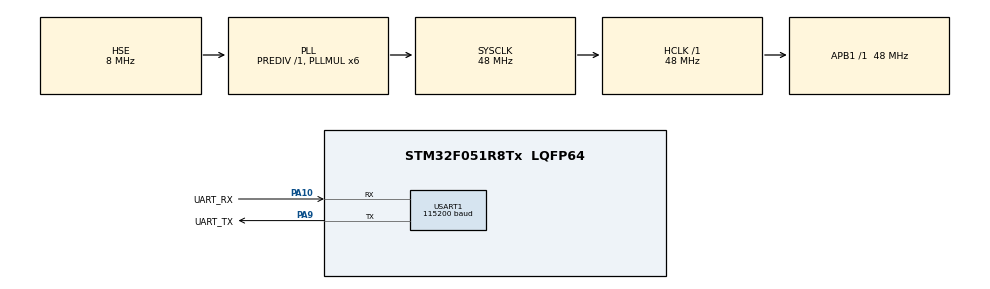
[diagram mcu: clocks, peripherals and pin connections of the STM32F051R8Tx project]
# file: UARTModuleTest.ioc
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Dma.Request0=USART1_RX
Dma.Request1=USART1_TX
Dma.USART1_RX.0.Direction=DMA_PERIPH_TO_MEMORY
Dma.USART1_RX.0.Instance=DMA1_Channel3
Dma.USART1_RX.0.MemDataAlignment=DMA_MDATAALIGN_BYTE
Dma.USART1_RX.0.MemInc=DMA_MINC_ENABLE
Dma.USART1_RX.0.Mode=DMA_NORMAL
Dma.USART1_RX.0.PeriphDataAlignment=DMA_PDATAALIGN_BYTE
Dma.USART1_RX.0.PeriphInc=DMA_PINC_DISABLE
Dma.USART1_RX.0.Priority=DMA_PRIORITY_LOW
Dma.USART1_TX.1.Direction=DMA_MEMORY_TO_PERIPH
Dma.USART1_TX.1.Instance=DMA1_Channel2
Dma.USART1_TX.1.MemDataAlignment=DMA_MDATAALIGN_BYTE
Dma.USART1_TX.1.MemInc=DMA_MINC_ENABLE
Dma.USART1_TX.1.Mode=DMA_NORMAL
Dma.USART1_TX.1.PeriphDataAlignment=DMA_PDATAALIGN_BYTE
Dma.USART1_TX.1.PeriphInc=DMA_PINC_DISABLE
Dma.USART1_TX.1.Priority=DMA_PRIORITY_LOW
Mcu.Family=STM32F0
Mcu.Name=STM32F051R8Tx
Mcu.Package=LQFP64
NVIC.DMA1_Channel2_3_IRQn=true\:0\:0\:false\:false\:true\:false\:true\:true
NVIC.USART1_IRQn=true\:0\:0\:false\:false\:true\:true\:true\:true
PA10.GPIO_Label=UART_RX
PA10.Mode=Asynchronous
PA10.Signal=USART1_RX
PA9.GPIO_Label=UART_TX
PA9.Mode=Asynchronous
PA9.Signal=USART1_TX
PF0-OSC_IN.Mode=HSE-External-Oscillator
PF0-OSC_IN.Signal=RCC_OSC_IN
PF1-OSC_OUT.Mode=HSE-External-Oscillator
PF1-OSC_OUT.Signal=RCC_OSC_OUT
ProjectManager.HeapSize=0x200
ProjectManager.StackSize=0x400
ProjectManager.TargetToolchain=MDK-ARM V5.32
RCC.AHBFreq_Value=48000000
RCC.APB1Freq_Value=48000000
RCC.APB1TimFreq_Value=48000000
RCC.HCLKFreq_Value=48000000
RCC.PLLMUL=RCC_PLL_MUL6
RCC.PLLSourceVirtual=RCC_PLLSOURCE_HSE
RCC.SYSCLKFreq_VALUE=48000000
RCC.SYSCLKSource=RCC_SYSCLKSOURCE_PLLCLK
USART1.BaudRate=115200
USART1.VirtualMode-Asynchronous=VM_ASYNC
board=custom

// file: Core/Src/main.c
/* USER CODE BEGIN Header */
/**
  ******************************************************************************
  * @file           : main.c
  * @brief          : Main program body
  ******************************************************************************
  * @attention
  *
  * Copyright (c) 2025 STMicroelectronics.
  * All rights reserved.
  *
  * This software is licensed under terms that can be found in the LICENSE file
  * in the root directory of this software component.
  * If no LICENSE file comes with this software, it is provided AS-IS.
  *
  ******************************************************************************
  */
/* USER CODE END Header */
#include "main.h"

/* USER CODE BEGIN PTD */

uint8_t msg_tx[512];
uint8_t msg_rx[16];
uint8_t* command_tx;

unsigned int buffer[3];

unsigned long Time;
/* USER CODE END PTD */

UART_HandleTypeDef huart1;
DMA_HandleTypeDef hdma_usart1_rx;
DMA_HandleTypeDef hdma_usart1_tx;

void SystemClock_Config(void);
static void MX_GPIO_Init(void);
static void MX_DMA_Init(void);
static void MX_USART1_UART_Init(void);
/* USER CODE BEGIN PFP */

void SendPackage(int *data, int len){

}

unsigned int calculateBCC(uint8_t *data, int length, bool get) // BCC CALCULATION 1-true 0-false
{
    unsigned int checksum = 0;
	if(!get){
    for (int i = 0; i < length-1; i++)
    {
        checksum ^= (int)data[i];

    }

		if(	checksum == data[length-1]){
    return 1;
		}
		else{
			return 0;
		}
	}
	else {

		  for (int i = 0; i < length-1; i++)
    {
        checksum ^= (int)data[i];

    }
		return checksum;

	}
}

void HAL_UART_RxCpltCallback(UART_HandleTypeDef *huart){          // PROBABLY NEED CALLBACK REWORK :3
    switch((int)msg_rx[0]){
		case(0x01):
				if(calculateBCC(msg_rx, 3, 0 )){
					// NEED TO MAKE CYCLE FOR LIST OF GAMES (BLALALA BLYLYLYL)
						msg_tx[0]=0x01;
						msg_tx[1]=0x01;
						msg_tx[2]=0x14;
						msg_tx[3]=calculateBCC(msg_tx, 4,1);
			    HAL_UART_Transmit(&huart1, msg_tx, 4 , 0xFFFF);}
				else{
						msg_tx[0]=0x01;
						msg_tx[1]=0xFF;
						msg_tx[2]=0xFF;
						msg_tx[3]=calculateBCC(msg_tx, 4,1);
					HAL_UART_Transmit(&huart1, msg_tx, 4 , 0xFFFF);}
		break;
		case(0x02):

		 if( ((int)msg_rx[1] == 0x0E) &&( !(int)msg_rx[2] && !(int)msg_rx[3]) && calculateBCC(msg_rx, 5, 0 ))  {
		    	HAL_UART_Transmit(&huart1, msg_tx, sprintf((char *)msg_tx, "pig\n\r"), 0xFFFF);
	 }

		break;

	}

}

/* USER CODE END PFP */

int main(void)
{

  /* MCU Configuration--------------------------------------------------------*/

  /* Reset of all peripherals, Initializes the Flash interface and the Systick. */
  HAL_Init();

  /* Configure the system clock */
  SystemClock_Config();

  /* Initialize all configured peripherals */
  MX_GPIO_Init();
  MX_DMA_Init();
  MX_USART1_UART_Init();

  /* Infinite loop */
  while (1)
  {

  }
}

void SystemClock_Config(void)
{
  RCC_OscInitTypeDef RCC_OscInitStruct = {0};
  RCC_ClkInitTypeDef RCC_ClkInitStruct = {0};
  RCC_PeriphCLKInitTypeDef PeriphClkInit = {0};

  /** Initializes the RCC Oscillators according to the specified parameters
  * in the RCC_OscInitTypeDef structure.
  */
  RCC_OscInitStruct.OscillatorType = RCC_OSCILLATORTYPE_HSE;
  RCC_OscInitStruct.HSEState = RCC_HSE_ON;
  RCC_OscInitStruct.PLL.PLLState = RCC_PLL_ON;
  RCC_OscInitStruct.PLL.PLLSource = RCC_PLLSOURCE_HSE;
  RCC_OscInitStruct.PLL.PLLMUL = RCC_PLL_MUL6;
  RCC_OscInitStruct.PLL.PREDIV = RCC_PREDIV_DIV1;
  if (HAL_RCC_OscConfig(&RCC_OscInitStruct) != HAL_OK)
  {
    Error_Handler();
  }

  /** Initializes the CPU, AHB and APB buses clocks
  */
  RCC_ClkInitStruct.ClockType = RCC_CLOCKTYPE_HCLK|RCC_CLOCKTYPE_SYSCLK
                              |RCC_CLOCKTYPE_PCLK1;
  RCC_ClkInitStruct.SYSCLKSource = RCC_SYSCLKSOURCE_PLLCLK;
  RCC_ClkInitStruct.AHBCLKDivider = RCC_SYSCLK_DIV1;
  RCC_ClkInitStruct.APB1CLKDivider = RCC_HCLK_DIV1;

  if (HAL_RCC_ClockConfig(&RCC_ClkInitStruct, FLASH_LATENCY_1) != HAL_OK)
  {
    Error_Handler();
  }
  PeriphClkInit.PeriphClockSelection = RCC_PERIPHCLK_USART1;
  PeriphClkInit.Usart1ClockSelection = RCC_USART1CLKSOURCE_PCLK1;
  if (HAL_RCCEx_PeriphCLKConfig(&PeriphClkInit) != HAL_OK)
  {
    Error_Handler();
  }
}

static void MX_USART1_UART_Init(void)
{

  huart1.Instance = USART1;
  huart1.Init.BaudRate = 115200;
  huart1.Init.WordLength = UART_WORDLENGTH_8B;
  huart1.Init.StopBits = UART_STOPBITS_1;
  huart1.Init.Parity = UART_PARITY_NONE;
  huart1.Init.Mode = UART_MODE_TX_RX;
  huart1.Init.HwFlowCtl = UART_HWCONTROL_NONE;
  huart1.Init.OverSampling = UART_OVERSAMPLING_16;
  huart1.Init.OneBitSampling = UART_ONE_BIT_SAMPLE_DISABLE;
  huart1.AdvancedInit.AdvFeatureInit = UART_ADVFEATURE_NO_INIT;
  if (HAL_UART_Init(&huart1) != HAL_OK)
  {
    Error_Handler();
  }

}

static void MX_DMA_Init(void)
{

  /* DMA controller clock enable */
  __HAL_RCC_DMA1_CLK_ENABLE();

  /* DMA interrupt init */
  /* DMA1_Channel2_3_IRQn interrupt configuration */
  HAL_NVIC_SetPriority(DMA1_Channel2_3_IRQn, 0, 0);
  HAL_NVIC_EnableIRQ(DMA1_Channel2_3_IRQn);

}

static void MX_GPIO_Init(void)
{

  /* GPIO Ports Clock Enable */
  __HAL_RCC_GPIOF_CLK_ENABLE();
  __HAL_RCC_GPIOA_CLK_ENABLE();

}

void Error_Handler(void)
{
  __disable_irq();
  while (1)
  {
  }
}
